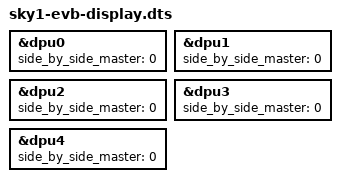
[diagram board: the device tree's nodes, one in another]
/*
 * Copyright 2024 Cix Technology Group Co., Ltd.
 *
 * SPDX-License-Identifier: BSD-3-Clause
 */

/dts-v1/;

#include "sky1-evb.dts"

&dpu0 {
	side_by_side_master = <0>;
};

&dpu1 {
	side_by_side_master = <0>;
};

&dpu2 {
	side_by_side_master = <0>;
};

&dpu3 {
	side_by_side_master = <0>;
};

&dpu4 {
	side_by_side_master = <0>;
};
